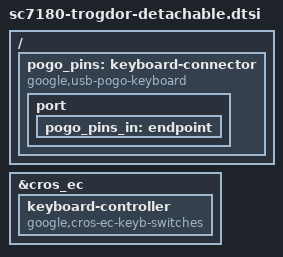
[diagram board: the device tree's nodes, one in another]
// SPDX-License-Identifier: (GPL-2.0+ OR MIT)
/*
 * Google Trogdor dts fragment for detachables
 *
 * Copyright 2024 Google LLC.
 */

/* This file must be included after sc7180-trogdor.dtsi to modify cros_ec */

/ {
	pogo_pins: keyboard-connector {
		compatible = "google,usb-pogo-keyboard";
		#address-cells = <1>;
		#size-cells = <0>;
		/* Detachable keyboard filled in by board */
		port {
			pogo_pins_in: endpoint {
				/* Endpoint filled in by board */
			};
		};
	};
};

&cros_ec {
	keyboard-controller {
		compatible = "google,cros-ec-keyb-switches";
	};
};
